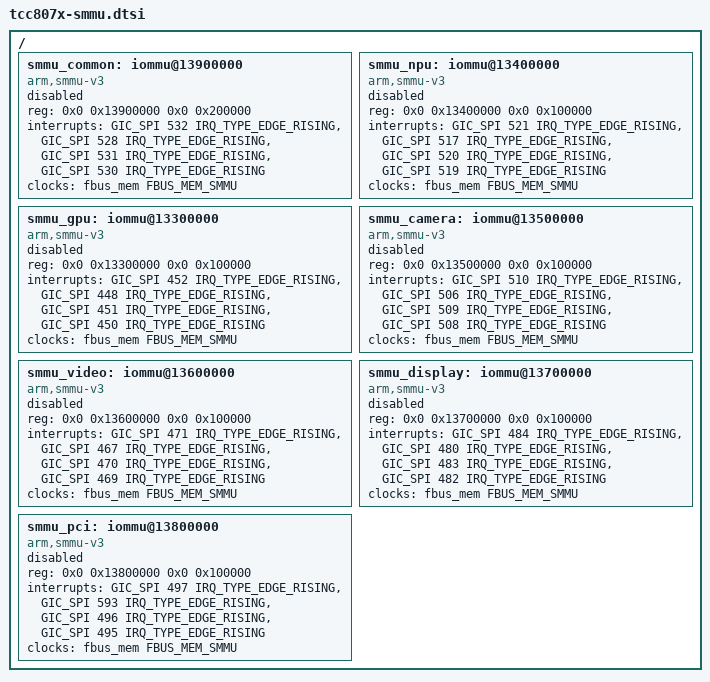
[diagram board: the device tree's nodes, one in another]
// SPDX-License-Identifier: (GPL-2.0-or-later OR MIT)
/*
 * Copyright (C) Telechips Inc.
 */

#include <dt-bindings/clock/telechips,tcc807x-clks.h>
#include <dt-bindings/interrupt-controller/arm-gic.h>

/ {
	smmu_common: iommu@13900000 {
		compatible = "arm,smmu-v3";
		reg = <0x0 0x13900000 0x0 0x200000>;
		interrupts = <GIC_SPI 532 IRQ_TYPE_EDGE_RISING>,
			     <GIC_SPI 528 IRQ_TYPE_EDGE_RISING>,
			     <GIC_SPI 531 IRQ_TYPE_EDGE_RISING>,
			     <GIC_SPI 530 IRQ_TYPE_EDGE_RISING>;
		interrupt-names = "eventq", "gerror", "priq", "cmdq-sync";
		#iommu-cells = <1>;
		clocks = <&fbus_mem FBUS_MEM_SMMU>;
		clock-names = "smmu-clk";
		status = "disabled";
	};

	smmu_npu: iommu@13400000 {
		compatible = "arm,smmu-v3";
		reg = <0x0 0x13400000 0x0 0x100000>;
		interrupts = <GIC_SPI 521 IRQ_TYPE_EDGE_RISING>,
			     <GIC_SPI 517 IRQ_TYPE_EDGE_RISING>,
			     <GIC_SPI 520 IRQ_TYPE_EDGE_RISING>,
			     <GIC_SPI 519 IRQ_TYPE_EDGE_RISING>;
		interrupt-names = "eventq", "gerror", "priq", "cmdq-sync";
		#iommu-cells = <1>;
		clocks = <&fbus_mem FBUS_MEM_SMMU>;
		clock-names = "smmu-clk";
		status = "disabled";
	};

	smmu_gpu: iommu@13300000 {
		compatible = "arm,smmu-v3";
		reg = <0x0 0x13300000 0x0 0x100000>;
		interrupts = <GIC_SPI 452 IRQ_TYPE_EDGE_RISING>,
			     <GIC_SPI 448 IRQ_TYPE_EDGE_RISING>,
			     <GIC_SPI 451 IRQ_TYPE_EDGE_RISING>,
			     <GIC_SPI 450 IRQ_TYPE_EDGE_RISING>;
		interrupt-names = "eventq", "gerror", "priq", "cmdq-sync";
		#iommu-cells = <1>;
		clocks = <&fbus_mem FBUS_MEM_SMMU>;
		clock-names = "smmu-clk";
		status = "disabled";
	};

	smmu_camera: iommu@13500000 {
		compatible = "arm,smmu-v3";
		reg = <0x0 0x13500000 0x0 0x100000>;
		interrupts = <GIC_SPI 510 IRQ_TYPE_EDGE_RISING>,
			     <GIC_SPI 506 IRQ_TYPE_EDGE_RISING>,
			     <GIC_SPI 509 IRQ_TYPE_EDGE_RISING>,
			     <GIC_SPI 508 IRQ_TYPE_EDGE_RISING>;
		interrupt-names = "eventq", "gerror", "priq", "cmdq-sync";
		#iommu-cells = <1>;
		clocks = <&fbus_mem FBUS_MEM_SMMU>;
		clock-names = "smmu-clk";
		status = "disabled";
	};

	smmu_video: iommu@13600000 {
		compatible = "arm,smmu-v3";
		reg = <0x0 0x13600000 0x0 0x100000>;
		interrupts = <GIC_SPI 471 IRQ_TYPE_EDGE_RISING>,
			     <GIC_SPI 467 IRQ_TYPE_EDGE_RISING>,
			     <GIC_SPI 470 IRQ_TYPE_EDGE_RISING>,
			     <GIC_SPI 469 IRQ_TYPE_EDGE_RISING>;
		interrupt-names = "eventq", "gerror", "priq", "cmdq-sync";
		#iommu-cells = <1>;
		clocks = <&fbus_mem FBUS_MEM_SMMU>;
		clock-names = "smmu-clk";
		status = "disabled";
	};

	smmu_display: iommu@13700000 {
		compatible = "arm,smmu-v3";
		reg = <0x0 0x13700000 0x0 0x100000>;
		interrupts = <GIC_SPI 484 IRQ_TYPE_EDGE_RISING>,
			     <GIC_SPI 480 IRQ_TYPE_EDGE_RISING>,
			     <GIC_SPI 483 IRQ_TYPE_EDGE_RISING>,
			     <GIC_SPI 482 IRQ_TYPE_EDGE_RISING>;
		interrupt-names = "eventq", "gerror", "priq", "cmdq-sync";
		#iommu-cells = <1>;
		clocks = <&fbus_mem FBUS_MEM_SMMU>;
		clock-names = "smmu-clk";
		status = "disabled";
	};

	smmu_pci: iommu@13800000 {
		compatible = "arm,smmu-v3";
		reg = <0x0 0x13800000 0x0 0x100000>;
		interrupts = <GIC_SPI 497 IRQ_TYPE_EDGE_RISING>,
			     <GIC_SPI 593 IRQ_TYPE_EDGE_RISING>,
			     <GIC_SPI 496 IRQ_TYPE_EDGE_RISING>,
			     <GIC_SPI 495 IRQ_TYPE_EDGE_RISING>;
		interrupt-names = "eventq", "gerror", "priq", "cmdq-sync";
		#iommu-cells = <1>;
		clocks = <&fbus_mem FBUS_MEM_SMMU>;
		clock-names = "smmu-clk";
		status = "disabled";
	};
};
